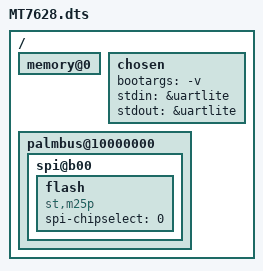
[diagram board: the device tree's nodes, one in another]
/dts-v1/;

/include/ "mediatek/mt7628an.dtsi"

/ {
	memory@0 {
		device_type = "memory";
//		reg = <0x0 0x8000000>;	/* 128MiB */
	};

	chosen {
		bootargs = "-v";
		stdin = &uartlite;
		stdout = &uartlite;
	};

	palmbus@10000000 {
		spi@b00 {
			flash {
				compatible = "st,m25p";
				spi-chipselect = <0>;
				#address-cells = <1>;
				#size-cells = <1>;

				/* Define slices, which are board-specific */
				/* For example:
				slice@0 {
					reg = <0x0 0x20000>;
					label = "U-Boot";
					read-only;
				};
				*/
			};
		};
	};
};
